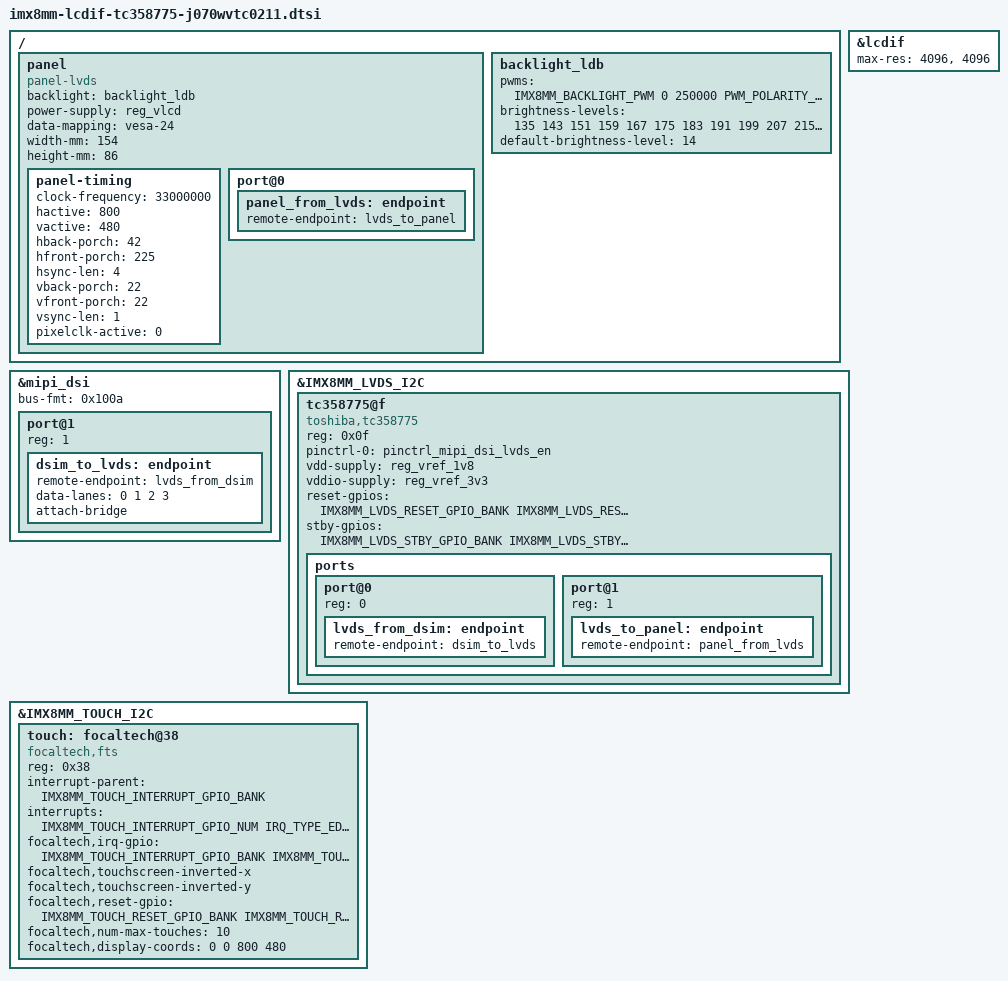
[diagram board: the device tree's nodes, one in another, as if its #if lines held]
/*
 * Copyright (C) 2020 F&S Elektronik Systeme GmbH
 *
 * This program is free software; you can redistribute it and/or modify
 * it under the terms of the GNU General Public License version 2 as
 * published by the Free Software Foundation.
 */

&lcdif {
	status = "okay";
	/* important to overwrite max-res otherwise DRM lcdif will fail to
	 * find a suitable connector
	 */
	max-res = <4096>, <4096>;
};

&mipi_dsi {
	status = "okay";

	bus-fmt = <0x100a>;

	port@1 {
		reg = <1>;
		dsim_to_lvds: endpoint {
			remote-endpoint = <&lvds_from_dsim>;
			data-lanes = <0 1 2 3>;
			attach-bridge;
		};
	};
};

&IMX8MM_LVDS_I2C {
	tc358775@f {

		compatible = "toshiba,tc358775";
		reg = <0x0f>;
		pinctrl-names = "default";
		pinctrl-0 = <&pinctrl_mipi_dsi_lvds_en>;
		vdd-supply = <&reg_vref_1v8>;
		vddio-supply = <&reg_vref_3v3>;

		reset-gpios = <&IMX8MM_LVDS_RESET_GPIO_BANK IMX8MM_LVDS_RESET_GPIO_NUM GPIO_ACTIVE_LOW>;
#ifdef IMX8MM_LVDS_STBY_GPIO_BANK
		stby-gpios  = <&IMX8MM_LVDS_STBY_GPIO_BANK IMX8MM_LVDS_STBY_GPIO_NUM GPIO_ACTIVE_LOW>;
#endif
		ports {
			#address-cells = <1>;
			#size-cells = <0>;

			port@0 {
				reg = <0>;

				lvds_from_dsim: endpoint {
					remote-endpoint = <&dsim_to_lvds>;
				};
			};

			port@1 {
				reg = <1>;

				lvds_to_panel: endpoint {
					remote-endpoint = <&panel_from_lvds>;
				};
			};
		};
	};
};

/{
	panel: panel {
		compatible = "panel-lvds";
		backlight = <&backlight_ldb>;
		power-supply = <&reg_vlcd>;

		data-mapping = "vesa-24";
		width-mm = <154>;
		height-mm = <86>;

		panel-timing {
				clock-frequency = <33000000>;
				hactive = <800>;
				vactive = <480>;
				hback-porch = <42>;
				hfront-porch = <225>;
				hsync-len = <4>;
				vback-porch = <22>;
				vfront-porch = <22>;
				vsync-len = <1>;
				pixelclk-active = <0>;
		};

		port@0 {
			panel_from_lvds: endpoint {
				remote-endpoint = <&lvds_to_panel>;
			};
		};
	};

	backlight_ldb: backlight_ldb {
		pwms = <&IMX8MM_BACKLIGHT_PWM 0 250000 PWM_POLARITY_INVERTED>;
		brightness-levels = <135 143 151 159 167 175 183 191
				     199 207 215 223 231 239 247 255>;
		default-brightness-level = <14>;
	};
};



&IMX8MM_TOUCH_I2C {
	/* touch I2C */
	touch: focaltech@38 {
		compatible = "focaltech,fts";
		reg = <0x38>;
		interrupt-parent = <&IMX8MM_TOUCH_INTERRUPT_GPIO_BANK>;
		interrupts = <IMX8MM_TOUCH_INTERRUPT_GPIO_NUM IRQ_TYPE_EDGE_FALLING>;
		focaltech,irq-gpio = <&IMX8MM_TOUCH_INTERRUPT_GPIO_BANK IMX8MM_TOUCH_INTERRUPT_GPIO_NUM IRQ_TYPE_EDGE_FALLING>;
#ifdef CONFIG_IMX8MM_INVERTED_XY
		focaltech,touchscreen-inverted-x;
		focaltech,touchscreen-inverted-y;
#endif
		focaltech,reset-gpio = <&IMX8MM_TOUCH_RESET_GPIO_BANK IMX8MM_TOUCH_RESET_GPIO_NUM GPIO_ACTIVE_LOW>;

		focaltech,num-max-touches = <10>;
		focaltech,display-coords = <0 0 800 480>;
	};
};

